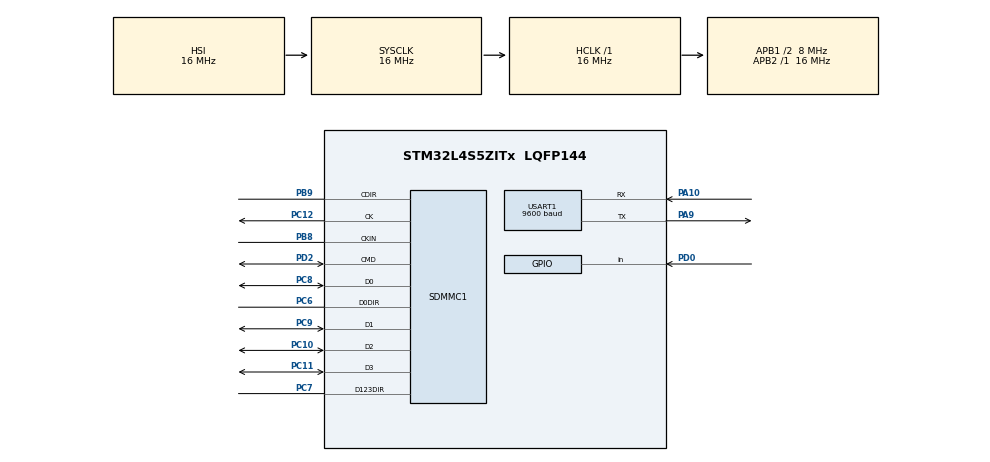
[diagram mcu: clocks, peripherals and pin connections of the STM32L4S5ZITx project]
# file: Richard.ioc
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FATFS.BSP.number=1
FATFS._MAX_SS=4096
FATFS0.BSP.STBoard=false
FATFS0.BSP.api=Unknown
FATFS0.BSP.i2caddr=0
FATFS0.BSP.instance=PD0
FATFS0.BSP.ip=GPIO
FATFS0.BSP.mode=Input
FATFS0.BSP.name=Detect_SDIO
FATFS0.BSP.solution=PD0
Mcu.Family=STM32L4
Mcu.Name=STM32L4S5ZITx
Mcu.Package=LQFP144
NVIC.PriorityGroup=NVIC_PRIORITYGROUP_4
NVIC.USART1_IRQn=true\:0\:0\:false\:false\:true\:true\:true
PA10.Mode=Asynchronous
PA10.Signal=USART1_RX
PA9.Mode=Asynchronous
PA9.Signal=USART1_TX
PB8.Mode=SD_4_bits_Wide_bus_dir_voltage_converter
PB8.Signal=SDMMC1_CKIN
PB9.Mode=SD_4_bits_Wide_bus_dir_voltage_converter
PB9.Signal=SDMMC1_CDIR
PC10.Mode=SD_4_bits_Wide_bus_dir_voltage_converter
PC10.Signal=SDMMC1_D2
PC11.Mode=SD_4_bits_Wide_bus_dir_voltage_converter
PC11.Signal=SDMMC1_D3
PC12.Mode=SD_4_bits_Wide_bus_dir_voltage_converter
PC12.Signal=SDMMC1_CK
PC6.Mode=SD_4_bits_Wide_bus_dir_voltage_converter
PC6.Signal=SDMMC1_D0DIR
PC7.Mode=SD_4_bits_Wide_bus_dir_voltage_converter
PC7.Signal=SDMMC1_D123DIR
PC8.Mode=SD_4_bits_Wide_bus_dir_voltage_converter
PC8.Signal=SDMMC1_D0
PC9.Mode=SD_4_bits_Wide_bus_dir_voltage_converter
PC9.Signal=SDMMC1_D1
PD0.Signal=GPIO_Input
PD2.Mode=SD_4_bits_Wide_bus_dir_voltage_converter
PD2.Signal=SDMMC1_CMD
PH0-OSC_IN\ (PH0).Mode=HSE-External-Oscillator
PH0-OSC_IN\ (PH0).Signal=RCC_OSC_IN
PH1-OSC_OUT\ (PH1).Mode=HSE-External-Oscillator
PH1-OSC_OUT\ (PH1).Signal=RCC_OSC_OUT
ProjectManager.HeapSize=0x200
ProjectManager.StackSize=0x400
ProjectManager.TargetToolchain=EWARM V8.32
RCC.ADCFreq_Value=24000000
RCC.AHBFreq_Value=16000000
RCC.APB1CLKDivider=RCC_HCLK_DIV2
RCC.APB1Freq_Value=8000000
RCC.APB1TimFreq_Value=16000000
RCC.APB2Freq_Value=16000000
RCC.APB2TimFreq_Value=16000000
RCC.CortexFreq_Value=2000000
RCC.Cortex_Div=SYSTICK_CLKSOURCE_HCLK_DIV8
RCC.HCLKFreq_Value=16000000
RCC.HSE_VALUE=24000000
RCC.HSI48_VALUE=48000000
RCC.HSI_VALUE=16000000
RCC.LSE_VALUE=32768
RCC.MSI_VALUE=4000000
RCC.PLLM1=2
RCC.PLLM2=4
RCC.PLLN=25
RCC.PLLP=RCC_PLLP_DIV8
RCC.PLLSAI1N=12
RCC.PLLSourceVirtual=RCC_PLLSOURCE_HSI
RCC.SYSCLKFreq_VALUE=16000000
RCC.SYSCLKSource=RCC_SYSCLKSOURCE_HSI
RCC.USART1CLockSelection=RCC_USART1CLKSOURCE_SYSCLK
RCC.USBFreq_Value=24000000
RCC.VCOOutputFreq_Value=200000000
SDMMC1.ClockDiv=3
USART1.BaudRate=9600
USART1.VirtualMode-Asynchronous=VM_ASYNC
VP_FATFS_VS_SDIO.Mode=SDIO
board=custom

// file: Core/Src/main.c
/* USER CODE BEGIN Header */
/**
  ******************************************************************************
  * @file           : main.c
  * @brief          : Main program body
  ******************************************************************************
  * @attention
  *
  * <h2><center>&copy; Copyright (c) 2021 STMicroelectronics.
  * All rights reserved.</center></h2>
  *
  * This software component is licensed by ST under Ultimate Liberty license
  * SLA0044, the "License"; You may not use this file except in compliance with
  * the License. You may obtain a copy of the License at:
  *                             www.st.com/SLA0044
  *
  ***************************************************************************
  */
/* USER CODE END Header */
#include "main.h"
#include "fatfs.h"
#include "sdmmc.h"
#include "usart.h"
#include "gpio.h"

/* USER CODE BEGIN Includes */
#include "UartRingbuffer.h"

/* USER CODE END Includes */
#include "file_handling.h"

void SystemClock_Config(void);

/* USER CODE BEGIN 0 */
char cmd = 0;
/* USER CODE END 0 */

int main(void)
{

  /* MCU Configuration--------------------------------------------------*/

  /* Reset of all peripherals, Initializes the Flash interface and the Systick. */
  HAL_Init();

  /* Configure the system clock */
  SystemClock_Config();

  /* Initialize all configured peripherals */
  MX_GPIO_Init();
  MX_SDMMC1_SD_Init();
  MX_FATFS_Init();
  MX_USART1_UART_Init();
  /* USER CODE BEGIN 2 */
    Ringbuf_init();
    mount_sd();
/* USER CODE END 2 */

  /* Infinite loop */
  while (1)
  {
  while (IsDataAvailable())
  	  {
  		  Get_string(buffer);
  		  int len = cmdlength(buffer);
  		  get_path();

  		  if (!(strncmp ("ls", buffer,len))) cmd = 'l';
  		  if (!(strncmp ("mkdir", buffer,len))) cmd = 'm';
  		  if (!(strncmp ("mkfil", buffer, len))) cmd = 'c';
  		  if (!(strncmp ("read", buffer, len))) cmd = 'r';
  		  if (!(strncmp ("write", buffer, len))) cmd = 'w';
  		  if (!(strncmp ("rm", buffer, len))) cmd = 'd';
  		  if (!(strncmp ("update", buffer, len))) cmd = 'u';
  		  if (!(strncmp ("checkfile", buffer, len))) cmd = 'f';
  		  if (!(strncmp ("checksd", buffer, len))) cmd = 's';

  		  switch (cmd)
  		  {
  		  	  case ('l'):
  		  			  scan_files(path);
  		  	  	  	  cmd =0;
  		  	  	  	  clear_buffer();
  		  	  	  	  clear_path();
  		  	  	  	  break;

  			  case ('m'):
  					  create_dir (path);
  			  	  	  cmd=0;
  			  	  	  clear_path();
  			  	  	  break;

  			  case ('c'):
  					  create_file(path);
  			  	  	  cmd = 0;
  			  	  	  clear_path();
  			  	  	  break;

  			  case ('r'):
  					  read_file (path);
  			  	  	  cmd = 0;
  			  	  	  clear_path();
  			  	  	  break;

  			  case ('d'):
  					  remove_file(path);
  			  	  	  cmd = 0;
  			  	  	  clear_path();
  			  	  	  break;

  			  case ('w'):
  					  write_file (path);
  			  	  	  cmd = 0;
  			  	  	  clear_path();
  			  	  	  break;

  			  case ('u'):
  					  update_file (path);
  			  	  	  cmd = 0;
  			  	  	  clear_path();
  			  	  	  break;

  			  case ('f'):
  					  check_file(path);
  			  	  	  cmd = 0;
  			  	  	  clear_path();
  			  	  	  break;

  			  case ('s'):
  					  check_sd();
  			  	  	  cmd = 0;
  			  	  	  clear_path();
  			  	  	  break;

  			  default :
  				  clear_buffer();
  				  clear_path();
  				  break;
  		  }
  	  }
    }
  }

void SystemClock_Config(void)
{
  RCC_OscInitTypeDef RCC_OscInitStruct = {0};
  RCC_ClkInitTypeDef RCC_ClkInitStruct = {0};
  RCC_PeriphCLKInitTypeDef PeriphClkInit = {0};

  /** Configure the main internal regulator output voltage
  */
  if (HAL_PWREx_ControlVoltageScaling(PWR_REGULATOR_VOLTAGE_SCALE1) != HAL_OK)
  {
    Error_Handler();
  }
  /** Initializes the RCC Oscillators according to the specified parameters
  * in the RCC_OscInitTypeDef structure.
  */
  RCC_OscInitStruct.OscillatorType = RCC_OSCILLATORTYPE_HSI;
  RCC_OscInitStruct.HSIState = RCC_HSI_ON;
  RCC_OscInitStruct.HSICalibrationValue = RCC_HSICALIBRATION_DEFAULT;
  RCC_OscInitStruct.PLL.PLLState = RCC_PLL_ON;
  RCC_OscInitStruct.PLL.PLLSource = RCC_PLLSOURCE_HSI;
  RCC_OscInitStruct.PLL.PLLM = 2;
  RCC_OscInitStruct.PLL.PLLN = 25;
  RCC_OscInitStruct.PLL.PLLP = RCC_PLLP_DIV8;
  RCC_OscInitStruct.PLL.PLLQ = RCC_PLLQ_DIV2;
  RCC_OscInitStruct.PLL.PLLR = RCC_PLLR_DIV2;
  if (HAL_RCC_OscConfig(&RCC_OscInitStruct) != HAL_OK)
  {
    Error_Handler();
  }
  /** Initializes the CPU, AHB and APB buses clocks
  */
  RCC_ClkInitStruct.ClockType = RCC_CLOCKTYPE_HCLK|RCC_CLOCKTYPE_SYSCLK
                              |RCC_CLOCKTYPE_PCLK1|RCC_CLOCKTYPE_PCLK2;
  RCC_ClkInitStruct.SYSCLKSource = RCC_SYSCLKSOURCE_HSI;
  RCC_ClkInitStruct.AHBCLKDivider = RCC_SYSCLK_DIV1;
  RCC_ClkInitStruct.APB1CLKDivider = RCC_HCLK_DIV2;
  RCC_ClkInitStruct.APB2CLKDivider = RCC_HCLK_DIV1;

  if (HAL_RCC_ClockConfig(&RCC_ClkInitStruct, FLASH_LATENCY_0) != HAL_OK)
  {
    Error_Handler();
  }
  PeriphClkInit.PeriphClockSelection = RCC_PERIPHCLK_USART1|RCC_PERIPHCLK_SDMMC1;
  PeriphClkInit.Usart1ClockSelection = RCC_USART1CLKSOURCE_SYSCLK;
  PeriphClkInit.Sdmmc1ClockSelection = RCC_SDMMC1CLKSOURCE_PLLP;
  if (HAL_RCCEx_PeriphCLKConfig(&PeriphClkInit) != HAL_OK)
  {
    Error_Handler();
  }
}

void Error_Handler(void)
{
  __disable_irq();
  while (1)
  {
  }
}

/************************ (C) COPYRIGHT STMicroelectronics *****END OF FILE****/
